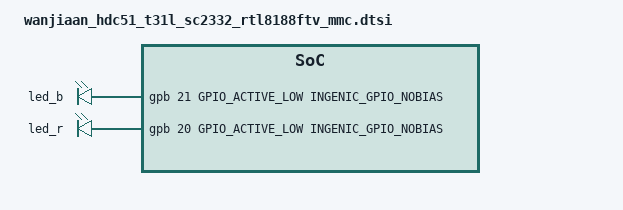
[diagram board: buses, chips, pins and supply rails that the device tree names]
// Wanjiaan HDC51 MMC Boot (T31L, SC2332, RTL8188FTV) per-board GPIO definitions.
// Injected into the kernel 4.4+ device tree; ignored on 3.10.

#include <dt-bindings/gpio/gpio.h>
#include <dt-bindings/pinctrl/ingenic-pinctrl.h>

/ {
	gpio-leds {
		compatible = "gpio-leds";

		led_b {
			label = "led_b";
			gpios = <&gpb 21 GPIO_ACTIVE_LOW INGENIC_GPIO_NOBIAS>;
			default-state = "off";
		};

		led_r {
			label = "led_r";
			gpios = <&gpb 20 GPIO_ACTIVE_LOW INGENIC_GPIO_NOBIAS>;
			default-state = "off";
		};
	};
};

/* Card detect; the family tree carries the reference pin. */
&msc0 {
	ingenic,cd-gpios = <&gpb 19 GPIO_ACTIVE_LOW INGENIC_GPIO_PULLUP>;
};
